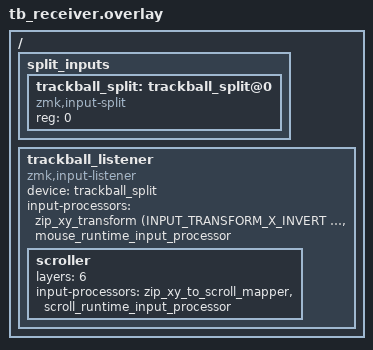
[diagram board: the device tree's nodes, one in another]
// Receiving end of the trackball's split input, for the dongle (central).
// Add this shield ON TOP of cornix_dongle_adapter to route trackball motion into HID.

#include <input/processors.dtsi>
#include <input/processors/runtime-input-processor.dtsi>
#include <dt-bindings/zmk/input_transform.h>

/ {
    split_inputs {
        #address-cells = <1>;
        #size-cells = <0>;

        trackball_split: trackball_split@0 {
            compatible = "zmk,input-split";
            reg = <0>;
        };
    };

    trackball_listener: trackball_listener {
        compatible = "zmk,input-listener";
        device = <&trackball_split>;

        // 1段目: センサーの取り付け向きの補正（静的・既に動作確認済み）
        //   上下だけ直したい場合は INPUT_TRANSFORM_Y_INVERT のみ、
        //   縦横が入れ替わっている場合は INPUT_TRANSFORM_XY_SWAP を足す。
        // 2段目: DYA Studio から実行時に調整できるプロセッサ
        //   感度・回転・軸スナップ・マウスレイヤーをWebから変更できる。
        input-processors =
            <&zip_xy_transform (INPUT_TRANSFORM_X_INVERT | INPUT_TRANSFORM_Y_INVERT)>,
            <&mouse_runtime_input_processor>;

        // レイヤー6（DELキー長押しで乗る Scroll レイヤー）にいる間だけ、
        // ボールの動きをスクロールに変換する。
        // scroll_runtime_input_processor を挟んであるので、
        // スクロール速度や軸スナップは DYA Studio から個別に調整できる。
        scroller {
            layers = <6>;
            input-processors =
                <&zip_xy_to_scroll_mapper>,
                <&scroll_runtime_input_processor>;
        };
    };
};
